# iqn_top register map
Vendor: Texas Instruments
Peripheral module from a debugger description file (folder Keystone2).
Registers are 32-bit, read-only, no defined reset value unless marked. A register's access mark holds for its fields unless they carry their own. Offsets are as the file gives them; lines under a group give offsets from that group; [hi:lo] are bit positions; {n}, {i} and the like mark numbered series; 'fields as' and 'values as' point back to an identical list; <NAME> marks a mode.

## IQN_TOP
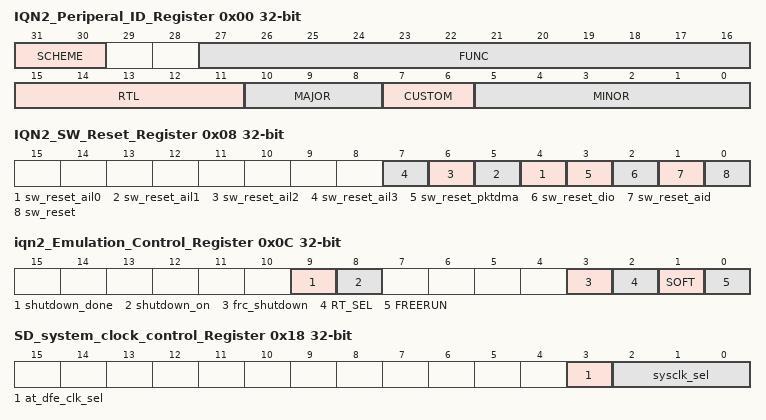
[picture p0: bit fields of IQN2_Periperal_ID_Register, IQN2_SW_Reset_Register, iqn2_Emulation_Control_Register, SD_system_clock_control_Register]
0x00 IQN2_Periperal_ID_Register — (1 of 1, stride 0)
  [31:30] SCHEME — Current scheme
  [27:16] FUNC — Function code assigned to IQN2
  [15:11] RTL — RTL Version R code
  [10:8] MAJOR — Major revision X code
  [7:6] CUSTOM — Custom version code
  [5:0] MINOR — Minor revision Y code
0x04 IQN2_Scratch_Register rw — (1 of 1, stride 0)
  [31:0] Scratch — This is the VC Scratch Field used for debug testing basic read and write to mmrs.
0x08 IQN2_SW_Reset_Register wo — (1 of 1, stride 0)
  [n+4] sw_reset_ail{n} (n=0..3) — These are software resets which reset various sections of IQN2.
  [3] sw_reset_pktdma — These are software resets which reset various sections of IQN2.
  [2] sw_reset_dio — These are software resets which reset various sections of IQN2.
  [1] sw_reset_aid — These are software resets which reset various sections of IQN2.
  [0] sw_reset — These are software resets which reset various sections of IQN2.
0x0C iqn2_Emulation_Control_Register access per field — (1 of 1, stride 0)
  [9] shutdown_done ro — Indicates the shutdown controller has finished shutting down and is holding the IQN2 in shutdown when set.
  [8] shutdown_on ro — Indicates the shutdown controller is processing a shutdown.
  [3] frc_shutdown rw — Forces the shutdown controller to shut down the entire IQN cleanly.
  [2] RT_SEL rw — RT_SEL bit
  [1] SOFT rw — SOFT bit. This bit is ignored by the IQN2. IQN2 always performs a graceful SOFT stop
  [0] FREERUN rw — FREERUN bit
0x14 Iqn2_data_trace_mux_select_Register rw — (1 of 1, stride 0)
  [1:0] vc_dtmux — Iqn2 data trace mux select Register selects which ail data trace to use
0x18 SD_system_clock_control_Register rw — (1 of 1, stride 0)
  [3] at_dfe_clk_sel — Selects dfe_pll_clk for the at and uat clock if =1. The selected sysclk derived from the SERDES TXBCLK is used when = 0. This should only be set when using DFE and not using the AIL
  [2:0] sysclk_sel — SD system clock control Register selects which SERDES txbclk to use for sys_clk. bits 0 and 1 select which serdes lane to use. bit 2 selects 1/2 the txbclk speed when set
0x20 CDMA_TX_takedown_status_lsb_Register — (1 of 1, stride 0)
  [31:0] tdown_status_l — CDMA TX takedown status lsb
0x24 CDMA_TX_takedown_status_msb_Register — (1 of 1, stride 0)
  [15:0] tdown_status_h — CDMA TX takedown status msb
0x28 CDMA_TX_enable_status_lsb_Register — (1 of 1, stride 0)
  [31:0] enable_status_l — CDMA TX enable status lsb
0x2C CDMA_TX_enable_status_msb_Register — (1 of 1, stride 0)
  [15:0] enable_status_h — CDMA TX enable status msb
0x30 CDMA_TX_packet_status_lsb_Register — (1 of 1, stride 0)
  [31:0] pkt_status_l — CDMA TX packet status lsb
0x34 CDMA_TX_packet_status_msb_Register — (1 of 1, stride 0)
  [15:0] pkt_status_h — CDMA TX packet status msb
0x38 CDMA_RX_takedown_status_lsb_Register — (1 of 1, stride 0)
  [31:0] tdown_status_l — CDMA RX takedown status lsb
0x3C CDMA_RX_takedown_status_msb_Register — (1 of 1, stride 0)
  [15:0] tdown_status_h — CDMA RX takedown status msb
0x40 CDMA_RX_enable_status_lsb_Register — (1 of 1, stride 0)
  [31:0] enable_status_l — CDMA RX enable status lsb
0x44 CDMA_RX_enable_status_msb_Register — (1 of 1, stride 0)
  [15:0] enable_status_h — CDMA RX enable status msb
0x48 CDMA_RX_packet_status_lsb_Register — (1 of 1, stride 0)
  [31:0] pkt_status_l — CDMA RX packet status lsb
0x4C CDMA_RX_packet_status_msb_Register — (1 of 1, stride 0)
  [15:0] pkt_status_h — CDMA RX packet status msb
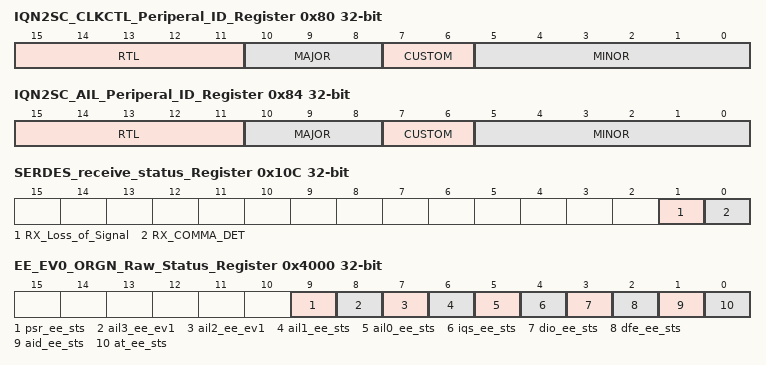
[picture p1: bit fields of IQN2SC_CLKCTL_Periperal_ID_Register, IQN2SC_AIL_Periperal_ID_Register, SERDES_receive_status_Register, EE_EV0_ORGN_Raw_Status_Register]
0x80 IQN2SC_CLKCTL_Periperal_ID_Register — (1 of 1, stride 0)
  [15:11] RTL — RTL Version R code
  [10:8] MAJOR — Major revision X code
  [7:6] CUSTOM — Custom version code
  [5:0] MINOR — Minor revision Y code
0x84 IQN2SC_AIL_Periperal_ID_Register — (1 of 1, stride 0)
  fields as IQN2SC_CLKCTL_Periperal_ID_Register
0x100 SERDES_transmit_status_Register — (1 of 4, stride 16)
  [0] link_status_ok — link clocks are ok to send and receive data. used in place of pll lock
0x10C SERDES_receive_status_Register — (1 of 4, stride 16)
  [1] RX_Loss_of_Signal — STSRX 1 The receiver frame synchronizer must have knowledge that each Ser-des port had detected a loss of signal condition so that the receiver can suppress events due to a loss of frame synchronization.
  [0] RX_COMMA_DET — STSRX 0 The receiver frame synchronizer must have knowledge that each Ser-des port had completed a requested byte alignment so that the byte alignment control logic can operate.
0x4000 EE_EV0_ORGN_Raw_Status_Register — (1 of 1, stride 0)
  [9] psr_ee_sts — PSR origination status.
  [8] ail3_ee_ev1 — AIL 3 origination status.
  [7] ail2_ee_ev1 — AIL 2 origination status.
  [6] ail1_ee_sts — AIL 1 origination status.
  [5] ail0_ee_sts — AIL 0 origination status.
  [4] iqs_ee_sts — IQS origination status.
  [3] dio_ee_sts — DIO origination status.
  [2] dfe_ee_sts — DFE origination status.
  [1] aid_ee_sts — AID origination status.
  [0] at_ee_sts — AT origination status.
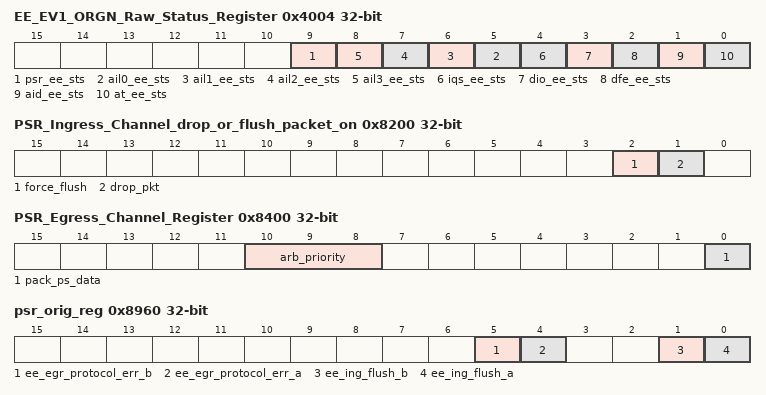
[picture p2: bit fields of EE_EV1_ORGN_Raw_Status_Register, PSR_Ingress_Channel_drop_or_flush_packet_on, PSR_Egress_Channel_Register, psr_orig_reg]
0x4004 EE_EV1_ORGN_Raw_Status_Register — (1 of 1, stride 0)
  [9] psr_ee_sts — PSR origination status.
  [n+5] ail{n}_ee_sts (n=0..3) — AIL {n} origination status.
  [4] iqs_ee_sts — IQS origination status.
  [3] dio_ee_sts — DIO origination status.
  [2] dfe_ee_sts — DFE origination status.
  [1] aid_ee_sts — AID origination status.
  [0] at_ee_sts — AT origination status.
0x4010 EE_EOI_EV_0_Register rw — (1 of 1, stride 0)
  [7:0] eoi_0_vector_reg — End Of Interrupt vector register for EV 0
0x4014 EE_EOI_EV_1_Register rw — (1 of 1, stride 0)
  [7:0] eoi_1_vector_reg — End Of Interrupt vector register for EV 1
0x4018 EE_EOI_CPPI_Register rw — (1 of 1, stride 0)
  [7:0] eoi_cppi_vector_reg — End Of Interrupt vector register for CPPI
0x8000 PSR_Egress_bw_limit_Configuration_Register rw — (1 of 1, stride 0)
  [11:8] bw_limit — Percent bandwidth limit setting for flushing a packet from a channel in the PKTDMA. 0 is 1/16 of VBUS bandwidth. Should be set to the maximum VBUS bandwidth expected to be used in normal operation rounded up to the next faster bandwidth setting. For
0x8004 PSR_Ingress_Configuration_Register rw — (1 of 1, stride 0)
  [0] ps_data_ext — Selects if the SI PS_FLAG bit 0 generates a PS_DATA cycle with the data coming from the dst_tag field of the INFO word.
0x8200 PSR_Ingress_Channel_drop_or_flush_packet_on rw — (1 of 1, stride 0)
  [2] force_flush — (For TI use only) set to 0. Forces the channel into continuous FLUSH. FLUSH operation will EOP any mid-flight packet and discard all new traffic for a given channel. Only known use case of this field is to support partial resets of i.e. individual links
  [1] drop_pkt — Normally set to 1. Drops the corrupted packet when FLUSH during mid packet. FLUSH likely caused by PktDMA buffer overflow for a given channel. (FLUSH also caused by force_flush)
0x8400 PSR_Egress_Channel_Register rw — (1 of 1, stride 0)
  [10:8] arb_priority — Arbitration priority for the channel on the PKTDMA PSI bus. 0 is highest priority.
  [0] pack_ps_data — Packs the PS_DATA into the dst_tag field of the INFO word when set. When not set PS_DATA is passed as a PS_DATA cycle with no modification of the INFO word dst_tag field. Only IQ data uses PS_DATA cycles and only OBSAI needing a 24 bit address passes
0x8800 ing_flush_a_Raw_Interrupt_Status — (1 of 1, stride 0)
  [31:0] err — Channel flush indication for ingress channels 0 through 31. An ingress flush error indicates a transfer to this PKTDMA channel was attempted when the channel was full which triggers a flush of the rest of the packet.
0x8804 ing_flush_a_Raw_Set wo — (1 of 1, stride 0)
  [31:0] err — Sets the corresponding bit in the raw_status register when written with a 1.
0x8808 ing_flush_a_Raw_Clear wo — (1 of 1, stride 0)
  [31:0] err — Clears the corresponding bit in the raw_status register when written with a 1.
0x880C ing_flush_a_EV0_Enable_Status — (1 of 1, stride 0)
  [31:0] err — When high enables the corresponding raw status bit to generate an interrupt.
0x8810 ing_flush_a_EV0_Enable_Set wo — (1 of 1, stride 0)
  [31:0] err — Sets the corresponding bit in the enable register when written with a 1.
0x8814 ing_flush_a_EV0_Enable_Clear wo — (1 of 1, stride 0)
  [31:0] err — Clears the corresponding bit in the enable register when written with a 1.
0x8818 ing_flush_a_EV1_Enable_Status — (1 of 1, stride 0)
  fields as ing_flush_a_EV0_Enable_Status
0x881C ing_flush_a_EV1_Enable_Set wo — (1 of 1, stride 0)
  fields as ing_flush_a_EV0_Enable_Set
0x8820 ing_flush_a_EV1_Enable_Clear wo — (1 of 1, stride 0)
  fields as ing_flush_a_EV0_Enable_Clear
0x8824 ing_flush_a_EV0_Enabled_Status — (1 of 1, stride 0)
  [31:0] err — When high indicates the interrupt is active due to the corresponding bit in the raw status register.
0x8828 ing_flush_a_EV1_Enabled_Status — (1 of 1, stride 0)
  fields as ing_flush_a_EV0_Enabled_Status
0x882C ing_flush_b_Raw_Interrupt_Status — (1 of 1, stride 0)
  [15:0] err — Channel flush indication for ingress channels 32 through 47. An ingress flush error indicates a transfer to this PKTDMA channel was attempted when the channel was full which triggers a flush of the rest of the packet.
0x8830 ing_flush_b_Raw_Set wo — (1 of 1, stride 0)
  [15:0] err — Sets the corresponding bit in the raw_status register when written with a 1.
0x8834 ing_flush_b_Raw_Clear wo — (1 of 1, stride 0)
  [15:0] err — Clears the corresponding bit in the raw_status register when written with a 1.
0x8838 ing_flush_b_EV0_Enable_Status — (1 of 1, stride 0)
  [15:0] err — When high enables the corresponding raw status bit to generate an interrupt.
0x883C ing_flush_b_EV0_Enable_Set wo — (1 of 1, stride 0)
  [15:0] err — Sets the corresponding bit in the enable register when written with a 1.
0x8840 ing_flush_b_EV0_Enable_Clear wo — (1 of 1, stride 0)
  [15:0] err — Clears the corresponding bit in the enable register when written with a 1.
0x8844 ing_flush_b_EV1_Enable_Status — (1 of 1, stride 0)
  fields as ing_flush_b_EV0_Enable_Status
0x8848 ing_flush_b_EV1_Enable_Set wo — (1 of 1, stride 0)
  fields as ing_flush_b_EV0_Enable_Set
0x884C ing_flush_b_EV1_Enable_Clear wo — (1 of 1, stride 0)
  fields as ing_flush_b_EV0_Enable_Clear
0x8850 ing_flush_b_EV0_Enabled_Status — (1 of 1, stride 0)
  [15:0] err — When high indicates the interrupt is active due to the corresponding bit in the raw status register.
0x8854 ing_flush_b_EV1_Enabled_Status — (1 of 1, stride 0)
  fields as ing_flush_b_EV0_Enabled_Status
0x88B0 egr_protocol_err_a_Raw_Interrupt_Status — (1 of 1, stride 0)
  [31:0] err — Protocol error indication of an unsupported data type or a missing PS_DATA transfer when one was expected for egress channels 0 through 31
0x88B4 egr_protocol_err_a_Raw_Set wo — (1 of 1, stride 0)
  fields as ing_flush_a_Raw_Set
0x88B8 egr_protocol_err_a_Raw_Clear wo — (1 of 1, stride 0)
  fields as ing_flush_a_Raw_Clear
0x88BC egr_protocol_err_a_EV0_Enable_Status — (1 of 1, stride 0)
  fields as ing_flush_a_EV0_Enable_Status
0x88C0 egr_protocol_err_a_EV0_Enable_Set wo — (1 of 1, stride 0)
  fields as ing_flush_a_EV0_Enable_Set
0x88C4 egr_protocol_err_a_EV0_Enable_Clear wo — (1 of 1, stride 0)
  fields as ing_flush_a_EV0_Enable_Clear
0x88C8 egr_protocol_err_a_EV1_Enable_Status — (1 of 1, stride 0)
  fields as ing_flush_a_EV0_Enable_Status
0x88CC egr_protocol_err_a_EV1_Enable_Set wo — (1 of 1, stride 0)
  fields as ing_flush_a_EV0_Enable_Set
0x88D0 egr_protocol_err_a_EV1_Enable_Clear wo — (1 of 1, stride 0)
  fields as ing_flush_a_EV0_Enable_Clear
0x88D4 egr_protocol_err_a_EV0_Enabled_Status — (1 of 1, stride 0)
  fields as ing_flush_a_EV0_Enabled_Status
0x88D8 egr_protocol_err_a_EV1_Enabled_Status — (1 of 1, stride 0)
  fields as ing_flush_a_EV0_Enabled_Status
0x88DC egr_protocol_err_b_Raw_Interrupt_Status — (1 of 1, stride 0)
  [15:0] err — Protocol error indication of an unsupported data type or a missing PS_DATA transfer when one was expected for egress channels 32 through 47
0x88E0 egr_protocol_err_b_Raw_Set wo — (1 of 1, stride 0)
  fields as ing_flush_b_Raw_Set
0x88E4 egr_protocol_err_b_Raw_Clear wo — (1 of 1, stride 0)
  fields as ing_flush_b_Raw_Clear
0x88E8 egr_protocol_err_b_EV0_Enable_Status — (1 of 1, stride 0)
  fields as ing_flush_b_EV0_Enable_Status
0x88EC egr_protocol_err_b_EV0_Enable_Set wo — (1 of 1, stride 0)
  fields as ing_flush_b_EV0_Enable_Set
0x88F0 egr_protocol_err_b_EV0_Enable_Clear wo — (1 of 1, stride 0)
  fields as ing_flush_b_EV0_Enable_Clear
0x88F4 egr_protocol_err_b_EV1_Enable_Status — (1 of 1, stride 0)
  fields as ing_flush_b_EV0_Enable_Status
0x88F8 egr_protocol_err_b_EV1_Enable_Set wo — (1 of 1, stride 0)
  fields as ing_flush_b_EV0_Enable_Set
0x88FC egr_protocol_err_b_EV1_Enable_Clear wo — (1 of 1, stride 0)
  fields as ing_flush_b_EV0_Enable_Clear
0x8900 egr_protocol_err_b_EV0_Enabled_Status — (1 of 1, stride 0)
  fields as ing_flush_b_EV0_Enabled_Status
0x8904 egr_protocol_err_b_EV1_Enabled_Status — (1 of 1, stride 0)
  fields as ing_flush_b_EV0_Enabled_Status
0x8960 psr_orig_reg — (1 of 1, stride 0)
  [5] ee_egr_protocol_err_b — If set a bit is set in the PSR ee_egr_protocol_err_b register.
  [4] ee_egr_protocol_err_a — If set a bit is set in the PSR ee_egr_protocol_err_a register.
  [1] ee_ing_flush_b — If set a bit is set in the PSR ee_ing_flush_b register.
  [0] ee_ing_flush_a — If set a bit is set in the PSR ee_ing_flush_a register.
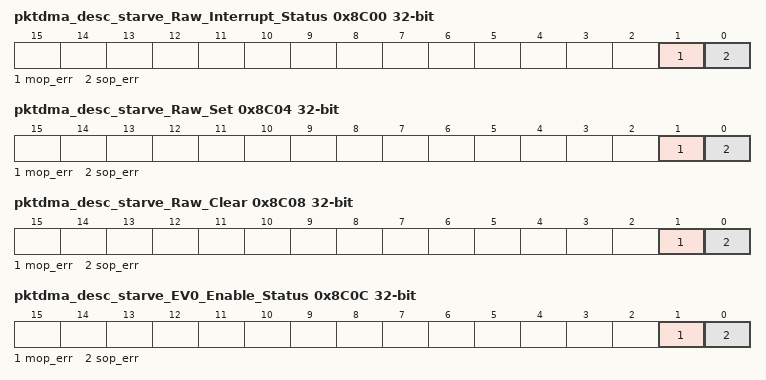
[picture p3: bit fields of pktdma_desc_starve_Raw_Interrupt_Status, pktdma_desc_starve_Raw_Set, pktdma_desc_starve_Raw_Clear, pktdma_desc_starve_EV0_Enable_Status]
0x8C00 pktdma_desc_starve_Raw_Interrupt_Status — (1 of 1, stride 0)
  [1] mop_err — PKTDMA MOP Descriptor starvation error There were not enough descriptors available for the PKTDMA to complete the transfer of a packet it already started.
  [0] sop_err — PKTDMA SOP Descriptor starvation error. There were not enough descriptors available for the PKTDMA to start the transfer of a packet.
0x8C04 pktdma_desc_starve_Raw_Set wo — (1 of 1, stride 0)
  [1] mop_err — Sets the corresponding bit in the raw_status register when set. Write only, self-clears.
  [0] sop_err — Sets the corresponding bit in the raw_status register when set. Write only, self-clears.
0x8C08 pktdma_desc_starve_Raw_Clear wo — (1 of 1, stride 0)
  [1] mop_err — Clears the corresponding bit in the raw_status register when set. Write only, self-clears.
  [0] sop_err — Clears the corresponding bit in the raw_status register when set. Write only, self-clears.
0x8C0C pktdma_desc_starve_EV0_Enable_Status — (1 of 1, stride 0)
  [1] mop_err — When set allows the corresponding bit in the raw_status register to generate the intr_sts interrupt. Read only.
  [0] sop_err — When set allows the corresponding bit in the raw_status register to generate the intr_sts interrupt. Read only.
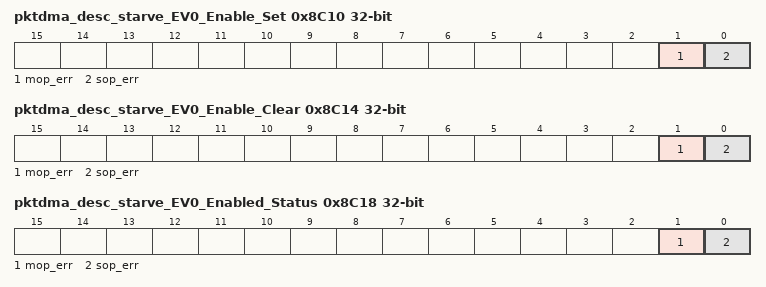
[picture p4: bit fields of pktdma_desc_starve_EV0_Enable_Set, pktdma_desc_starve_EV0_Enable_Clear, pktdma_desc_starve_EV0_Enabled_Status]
0x8C10 pktdma_desc_starve_EV0_Enable_Set wo — (1 of 1, stride 0)
  [1] mop_err — Sets the corresponding bit in the enable register when set. Write only, self-clears.
  [0] sop_err — Sets the corresponding bit in the enable register when set. Write only, self-clears.
0x8C14 pktdma_desc_starve_EV0_Enable_Clear wo — (1 of 1, stride 0)
  [1] mop_err — Clears the corresponding bit in the enable register when set. Write only, self-clears.
  [0] sop_err — Clears the corresponding bit in the enable register when set. Write only, self-clears.
0x8C18 pktdma_desc_starve_EV0_Enabled_Status — (1 of 1, stride 0)
  [1] mop_err — AND-ed raw_status bits with the corresponding bit in the enable_status register. Read only.
  [0] sop_err — AND-ed raw_status bits with the corresponding bit in the enable_status register. Read only.
